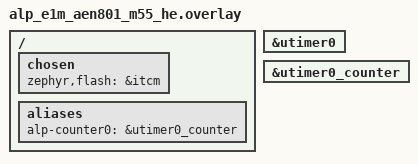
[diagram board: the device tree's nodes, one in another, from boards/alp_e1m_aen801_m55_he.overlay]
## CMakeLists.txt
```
# SPDX-License-Identifier: Apache-2.0
#
# On-silicon UTIMER counter validation for the E1M-AEN801 (Alif Ensemble E8),
# free-running the utimer0 counter through the portable Zephyr counter_* class
# API over the alp-sdk Tier-1.5 counter_alif_utimer driver.  A RAM console
# carries the PASS/FAIL line; the human ALSO reads the UTIMER CNTR register over
# J-Link to confirm the count advances independently of any printk.
#
# Standalone Zephyr app (no alp_project.py board.yaml flow): build with
#   ZEPHYR_BASE=<zephyr-base> west build \
#     -b alp_e1m_aen801_m55_he/ae822fa0e5597ls0/rtss_he <this-dir> -- \
#     "-DEXTRA_ZEPHYR_MODULES=<alp-sdk>;<hal_alif>"
# Zephyr applies boards/<fully-qualified-board>.overlay by itself.

cmake_minimum_required(VERSION 3.20)

find_package(Zephyr REQUIRED HINTS $ENV{ZEPHYR_BASE})
project(aen_counter_utimer_regcheck LANGUAGES C)

target_sources(app PRIVATE src/main.c)
```

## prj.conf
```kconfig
# SPDX-License-Identifier: Apache-2.0
#
# Bench config for the UTIMER counter regcheck on the E1M-AEN801 (Alif Ensemble
# E8).

# --- Console -----------------------------------------------------------------
# Console: Alp UART console -- E1M edge UART0 (Alif UART5, P3_4/P3_5, 115200
# 8N1, NS16550), the E1M-AEN801 carrier console. The board _defconfig already
# selects it; we set it explicitly here so the example is self-describing.
CONFIG_SERIAL=y
CONFIG_CONSOLE=y
CONFIG_UART_CONSOLE=y
CONFIG_UART_INTERRUPT_DRIVEN=y
# Serial-less bench? Comment the four lines above and uncomment these to read
# 'ram_console_buf' over SWD instead:
# CONFIG_RAM_CONSOLE=y
# CONFIG_RAM_CONSOLE_BUFFER_SIZE=2048
# CONFIG_UART_CONSOLE=n
CONFIG_PRINTK=y

# --- UTIMER counter ----------------------------------------------------------
# CONFIG_COUNTER_ALIF_UTIMER (the Tier-1.5 driver) is `default y` under `if
# ALP_SDK` once the okay'd "alif,utimer-counter" child node exists, so ALP_SDK
# MUST be on to surface it; COUNTER pulls in the Zephyr counter subsystem the
# driver registers against.
CONFIG_ALP_SDK=y
CONFIG_COUNTER=y

# Keep the image small + deterministic for a RAM-run.
CONFIG_LOG=n
```

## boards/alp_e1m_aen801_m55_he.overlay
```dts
/*
 * Copyright (c) 2026 Alp Lab AB
 * SPDX-License-Identifier: Apache-2.0
 *
 * On-silicon UTIMER counter validation overlay for the E1M-AEN801 (Alif
 * Ensemble E8, M55-HE), bench RAM-run via J-Link.
 *
 * Validates the alp-sdk Tier-1.5 counter_alif_utimer driver on utimer0.  The
 * "alif,utimer" PARENT (utimer@0x48001000) holds the two reg windows -- the
 * per-timer block "timer" 0x48001000 (CNTR / COMPARE / INTERRUPT) and the shared
 * "global" block 0x48000000 (per-timer START / STOP / CLK_ENABLE) -- and the
 * counter_alif_utimer driver binds the "alif,utimer-counter" CHILD node
 * (utimer0_counter), reaching the parent via DT_INST_PARENT() for those windows
 * + timer-id + clock-frequency + the comp_capt_a IRQ.  BOTH the parent and the
 * child must be okay'd for the driver to instantiate a device.
 *
 * UTIMER per-timer register map for utimer0 (parent reg[0] base 0x48001000), the
 * ground-truth the human reads over J-Link to confirm the count advances:
 *     CNTR (live counter value) = 0x48001000 + 0x44 = 0x48001044
 *   (offset per the hal_alif utimer.c CNTR register; confirm vs the Alif TRM at
 *    bench bring-up -- the in-firmware counter_get_value() is the primary
 *    evidence and does not depend on this address.)
 *
 * The utimer0 parent carries clock-frequency = <100000000> (a PLACEHOLDER tick
 * rate from the dtsi; see the bench note in main.c) -- it only scales
 * us<->ticks, not the register programming, so the count still advances
 * correctly.
 */

/*
 * MANDATORY bench RAM-run retarget: run from ITCM so J-Link can loadbin+run
 * without programming MRAM, and drop the MCUboot code-partition fixup.
 */
/ {
	chosen {
		/* PATH-REFERENCE form (&itcm), NOT the <&itcm> phandle-array form:
		 * the phandle-array form yields CONFIG_FLASH_SIZE=0 and the image
		 * overflows the (empty) FLASH region at link time. */
		zephyr,flash = &itcm;
		/delete-property/ zephyr,code-partition;
	};

	aliases {
		/* The wildcard counter backend resolves alp-counter0; keep the
		 * alias here so a portable alp_counter_open() path also works. */
		alp-counter0 = &utimer0_counter;
	};
};

/* Enable BOTH the parent timer block and its counter child -- the driver binds
 * the child but reads the reg/IRQ/clock off the parent. */
&utimer0 {
	status = "okay";
};

&utimer0_counter {
	status = "okay";
};
```

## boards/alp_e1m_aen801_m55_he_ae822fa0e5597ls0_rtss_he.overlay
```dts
/*
 * Copyright (c) 2026 Alp Lab AB
 * SPDX-License-Identifier: Apache-2.0
 *
 * On-silicon UTIMER counter validation overlay for the E1M-AEN801 (Alif
 * Ensemble E8, M55-HE), bench RAM-run via J-Link.
 *
 * Validates the alp-sdk Tier-1.5 counter_alif_utimer driver on utimer0.  The
 * "alif,utimer" PARENT (utimer@0x48001000) holds the two reg windows -- the
 * per-timer block "timer" 0x48001000 (CNTR / COMPARE / INTERRUPT) and the shared
 * "global" block 0x48000000 (per-timer START / STOP / CLK_ENABLE) -- and the
 * counter_alif_utimer driver binds the "alif,utimer-counter" CHILD node
 * (utimer0_counter), reaching the parent via DT_INST_PARENT() for those windows
 * + timer-id + clock-frequency + the comp_capt_a IRQ.  BOTH the parent and the
 * child must be okay'd for the driver to instantiate a device.
 *
 * UTIMER per-timer register map for utimer0 (parent reg[0] base 0x48001000), the
 * ground-truth the human reads over J-Link to confirm the count advances:
 *     CNTR (live counter value) = 0x48001000 + 0xA0 = 0x480010A0
 *   (per-timer offset 0xA0 = UTIMER_CNTR per the DFP AE822FA0E5597 rtss_he
 *    soc.h; offset 0x44 is UTIMER_DMA_CLEAR_SRC_B_1, NOT the counter -- the
 *    in-firmware counter_get_value() is the primary evidence and does not
 *    depend on this address.)
 *
 * The utimer0 parent carries clock-frequency = <100000000> (a PLACEHOLDER tick
 * rate from the dtsi; see the bench note in main.c) -- it only scales
 * us<->ticks, not the register programming, so the count still advances
 * correctly.
 */

/*
 * MANDATORY bench RAM-run retarget: run from ITCM so J-Link can loadbin+run
 * without programming MRAM, and drop the MCUboot code-partition fixup.
 */
/ {
	chosen {
		/* PATH-REFERENCE form (&itcm), NOT the <&itcm> phandle-array form:
		 * the phandle-array form yields CONFIG_FLASH_SIZE=0 and the image
		 * overflows the (empty) FLASH region at link time. */
		zephyr,flash = &itcm;
		/delete-property/ zephyr,code-partition;
	};

	aliases {
		/* The wildcard counter backend resolves alp-counter0; keep the
		 * alias here so a portable alp_counter_open() path also works. */
		alp-counter0 = &utimer0_counter;
	};
};

/* Enable BOTH the parent timer block and its counter child -- the driver binds
 * the child but reads the reg/IRQ/clock off the parent. */
&utimer0 {
	status = "okay";
};

&utimer0_counter {
	status = "okay";
};
```

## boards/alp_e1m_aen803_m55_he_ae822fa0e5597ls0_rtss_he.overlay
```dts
/*
 * Copyright (c) 2026 Alp Lab AB
 * SPDX-License-Identifier: Apache-2.0
 *
 * On-silicon UTIMER counter validation overlay for the E1M-AEN803 (Alif
 * Ensemble E8, M55-HE), bench RAM-run via J-Link.
 *
 * Validates the alp-sdk Tier-1.5 counter_alif_utimer driver on utimer0.  The
 * "alif,utimer" PARENT (utimer@0x48001000) holds the two reg windows -- the
 * per-timer block "timer" 0x48001000 (CNTR / COMPARE / INTERRUPT) and the shared
 * "global" block 0x48000000 (per-timer START / STOP / CLK_ENABLE) -- and the
 * counter_alif_utimer driver binds the "alif,utimer-counter" CHILD node
 * (utimer0_counter), reaching the parent via DT_INST_PARENT() for those windows
 * + timer-id + clock-frequency + the comp_capt_a IRQ.  BOTH the parent and the
 * child must be okay'd for the driver to instantiate a device.
 *
 * UTIMER per-timer register map for utimer0 (parent reg[0] base 0x48001000), the
 * ground-truth the human reads over J-Link to confirm the count advances:
 *     CNTR (live counter value) = 0x48001000 + 0xA0 = 0x480010A0
 *   (per-timer offset 0xA0 = UTIMER_CNTR per the DFP AE822FA0E5597 rtss_he
 *    soc.h; offset 0x44 is UTIMER_DMA_CLEAR_SRC_B_1, NOT the counter -- the
 *    in-firmware counter_get_value() is the primary evidence and does not
 *    depend on this address.)
 *
 * The utimer0 parent carries clock-frequency = <100000000> (a PLACEHOLDER tick
 * rate from the dtsi; see the bench note in main.c) -- it only scales
 * us<->ticks, not the register programming, so the count still advances
 * correctly.
 */

/*
 * MANDATORY bench RAM-run retarget: run from ITCM so J-Link can loadbin+run
 * without programming MRAM, and drop the MCUboot code-partition fixup.
 */
/ {
	chosen {
		/* PATH-REFERENCE form (&itcm), NOT the <&itcm> phandle-array form:
		 * the phandle-array form yields CONFIG_FLASH_SIZE=0 and the image
		 * overflows the (empty) FLASH region at link time. */
		zephyr,flash = &itcm;
		/delete-property/ zephyr,code-partition;
	};

	aliases {
		/* The wildcard counter backend resolves alp-counter0; keep the
		 * alias here so a portable alp_counter_open() path also works. */
		alp-counter0 = &utimer0_counter;
	};
};

/* Enable BOTH the parent timer block and its counter child -- the driver binds
 * the child but reads the reg/IRQ/clock off the parent. */
&utimer0 {
	status = "okay";
};

&utimer0_counter {
	status = "okay";
};
```

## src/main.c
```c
/*
 * Copyright (c) 2026 Alp Lab AB
 * SPDX-License-Identifier: Apache-2.0
 *
 * On-silicon UTIMER counter validation for the E1M-AEN801 (Alif Ensemble E8)
 * over the alp-sdk Tier-1.5 counter_alif_utimer driver (ADR 0017 Tier-1.5,
 * "alif,utimer-counter" -- a thin Zephyr counter-class shell over the Apache-2.0
 * hal_alif alif_utimer_* register library).
 *
 * What it proves
 * --------------
 * Start the free-running 32-bit utimer0 counter through the PORTABLE Zephyr
 * counter_* class API and confirm the count actually ADVANCES on silicon, two
 * independent ways:
 *
 *   1. in-firmware:  this app reads counter_get_value() twice with a busy-wait
 *      between, prints both raw tick values + their delta + every API return
 *      code, and a single 'RESULT PASS:' / 'RESULT FAIL:' line.
 *   2. over J-Link:  the human reads the UTIMER CNTR register with mem32
 *      (0x480010A0, see the overlay) across the same window -- the ground truth
 *      on silicon, independent of any printk.
 *
 * Counter node shape (see the overlay): the counter_alif_utimer driver binds the
 * "alif,utimer-counter" CHILD (utimer0_counter) and reaches the "alif,utimer"
 * PARENT (utimer0 @ 0x48001000) for the timer/global reg windows + timer-id +
 * clock-frequency + the comp_capt_a IRQ.
 *
 * BENCH NOTE -- tick rate: the parent's clock-frequency is the dtsi PLACEHOLDER
 * 100 MHz; the counter is expected to advance at a HIGHER real rate (early bench
 * observation ~400 MHz tick).  A wrong clock-frequency ONLY mis-scales
 * counter_us_to_ticks(); it does NOT change whether the count advances, so this
 * test (advance == PASS) is valid regardless.  Do NOT hard-code a "real" rate
 * here -- the authoritative value is a silicon HW fact from the Alif Ensemble E8
 * TRM (pending bench), per the alp-sdk pending-hw-configs policy.
 *
 * Console is the RAM buffer 'ram_console_buf' (see prj.conf); the bench UART is
 * not wired to USB.  BENCH-VALIDATION app -- not a customer teaching example.
 */

#include <zephyr/kernel.h>
#include <zephyr/device.h>
#include <zephyr/drivers/counter.h>

/* The counter device is the "alif,utimer-counter" CHILD node (utimer0_counter);
 * the driver binds the child, not the alif,utimer parent. */
#define COUNTER_NODE DT_NODELABEL(utimer0_counter)

/* Dwell between the two counter reads.  ~2 ms is plenty for the count to move at
 * any plausible UTIMER tick rate (100 MHz placeholder -> 200000 ticks; a faster
 * real rate only widens the delta), and short enough not to wrap a 32-bit
 * free-running counter. */
#define READ_GAP_US 2000U

static const struct device *const counter0 = DEVICE_DT_GET(COUNTER_NODE);

int main(void)
{
	int      rc;
	uint32_t freq, top, v1, v2, delta;

	printk("\n=== AEN801 UTIMER counter bench "
	       "(counter_alif_utimer / utimer0_counter) ===\n");

	/* 1. device readiness.  If the counter node did not instantiate a device
	 *    the build would have failed at link (undefined __device_dts_ord_*),
	 *    so reaching here means the device object exists -- check it is ready. */
	if (!device_is_ready(counter0)) {
		printk("RESULT FAIL: utimer0_counter device not ready\n");
		return 0;
	}
	printk("utimer0_counter device ready\n");

	/* 2. static parameters.  freq is the parent clock-frequency (placeholder
	 *    100 MHz this build); top is the free-running 32-bit reload value
	 *    (expect 0xFFFFFFFF). */
	freq = counter_get_frequency(counter0);
	top  = counter_get_top_value(counter0);
	printk("counter_get_frequency() = %u Hz (dtsi placeholder; real rate per TRM)\n", freq);
	printk("counter_get_top_value() = 0x%08x\n", top);

	/* 3. start the free-running counter. */
	rc = counter_start(counter0);
	printk("counter_start() rc=%d\n", rc);
	if (rc != 0) {
		printk("RESULT FAIL: counter_start rc=%d\n", rc);
		return 0;
	}

	/* 4. first reading. */
	rc = counter_get_value(counter0, &v1);
	printk("counter_get_value() #1 rc=%d  ticks=0x%08x (%u)\n", rc, v1, v1);
	if (rc != 0) {
		printk("RESULT FAIL: counter_get_value #1 rc=%d\n", rc);
		return 0;
	}

	/* --- J-Link readback window #1: mem32 0x480010A0 (UTIMER0 CNTR) --- */

	/* 5. let the counter advance, then read again. */
	k_busy_wait(READ_GAP_US);

	rc = counter_get_value(counter0, &v2);
	printk("counter_get_value() #2 rc=%d  ticks=0x%08x (%u)\n", rc, v2, v2);
	if (rc != 0) {
		printk("RESULT FAIL: counter_get_value #2 rc=%d\n", rc);
		return 0;
	}

	/* --- J-Link readback window #2: mem32 0x480010A0 (UTIMER0 CNTR) --- */

	/* 6. verdict: a free-running up-counter must have advanced between the two
	 *    reads.  Use unsigned wrap so a (very unlikely) 32-bit wrap across the
	 *    ~2 ms gap still yields the true positive delta. */
	delta = v2 - v1;
	printk("delta (v2 - v1) = %u ticks over ~%u us\n", delta, READ_GAP_US);

	if (delta != 0U) {
		printk("RESULT PASS: utimer0 counter advances "
		       "(v1=0x%08x v2=0x%08x delta=%u ticks over ~%u us)\n",
		       v1,
		       v2,
		       delta,
		       READ_GAP_US);
	} else {
		printk("RESULT FAIL: counter did not advance "
		       "(v1=0x%08x v2=0x%08x delta=0)\n",
		       v1,
		       v2);
	}

	/* Leave the counter running + park; CNTR stays live for the J-Link read. */
	return 0;
}
```
